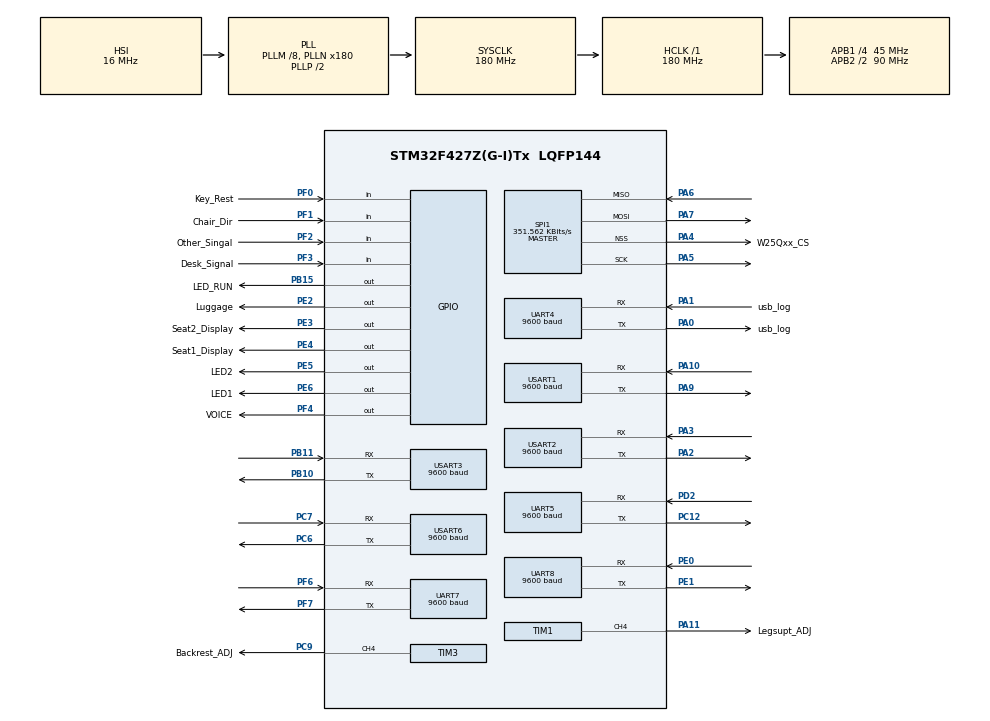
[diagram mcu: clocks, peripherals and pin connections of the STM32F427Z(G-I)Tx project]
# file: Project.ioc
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Dma.Request0=UART4_RX
Dma.Request1=USART1_RX
Dma.Request2=USART2_RX
Dma.Request3=USART3_RX
Dma.Request4=UART5_RX
Dma.Request5=USART6_RX
Dma.Request6=UART7_RX
Dma.Request7=UART8_RX
Dma.UART4_RX.0.Direction=DMA_PERIPH_TO_MEMORY
Dma.UART4_RX.0.FIFOMode=DMA_FIFOMODE_DISABLE
Dma.UART4_RX.0.Instance=DMA1_Stream2
Dma.UART4_RX.0.MemDataAlignment=DMA_MDATAALIGN_BYTE
Dma.UART4_RX.0.MemInc=DMA_MINC_ENABLE
Dma.UART4_RX.0.Mode=DMA_NORMAL
Dma.UART4_RX.0.PeriphDataAlignment=DMA_PDATAALIGN_BYTE
Dma.UART4_RX.0.PeriphInc=DMA_PINC_DISABLE
Dma.UART4_RX.0.Priority=DMA_PRIORITY_LOW
Dma.UART5_RX.4.Direction=DMA_PERIPH_TO_MEMORY
Dma.UART5_RX.4.FIFOMode=DMA_FIFOMODE_DISABLE
Dma.UART5_RX.4.Instance=DMA1_Stream0
Dma.UART5_RX.4.MemDataAlignment=DMA_MDATAALIGN_BYTE
Dma.UART5_RX.4.MemInc=DMA_MINC_ENABLE
Dma.UART5_RX.4.Mode=DMA_NORMAL
Dma.UART5_RX.4.PeriphDataAlignment=DMA_PDATAALIGN_BYTE
Dma.UART5_RX.4.PeriphInc=DMA_PINC_DISABLE
Dma.UART5_RX.4.Priority=DMA_PRIORITY_LOW
Dma.UART7_RX.6.Direction=DMA_PERIPH_TO_MEMORY
Dma.UART7_RX.6.FIFOMode=DMA_FIFOMODE_DISABLE
Dma.UART7_RX.6.Instance=DMA1_Stream3
Dma.UART7_RX.6.MemDataAlignment=DMA_MDATAALIGN_BYTE
Dma.UART7_RX.6.MemInc=DMA_MINC_ENABLE
Dma.UART7_RX.6.Mode=DMA_NORMAL
Dma.UART7_RX.6.PeriphDataAlignment=DMA_PDATAALIGN_BYTE
Dma.UART7_RX.6.PeriphInc=DMA_PINC_DISABLE
Dma.UART7_RX.6.Priority=DMA_PRIORITY_LOW
Dma.UART8_RX.7.Direction=DMA_PERIPH_TO_MEMORY
Dma.UART8_RX.7.FIFOMode=DMA_FIFOMODE_DISABLE
Dma.UART8_RX.7.Instance=DMA1_Stream6
Dma.UART8_RX.7.MemDataAlignment=DMA_MDATAALIGN_BYTE
Dma.UART8_RX.7.MemInc=DMA_MINC_ENABLE
Dma.UART8_RX.7.Mode=DMA_NORMAL
Dma.UART8_RX.7.PeriphDataAlignment=DMA_PDATAALIGN_BYTE
Dma.UART8_RX.7.PeriphInc=DMA_PINC_DISABLE
Dma.UART8_RX.7.Priority=DMA_PRIORITY_LOW
Dma.USART1_RX.1.Direction=DMA_PERIPH_TO_MEMORY
Dma.USART1_RX.1.FIFOMode=DMA_FIFOMODE_DISABLE
Dma.USART1_RX.1.Instance=DMA2_Stream2
Dma.USART1_RX.1.MemDataAlignment=DMA_MDATAALIGN_BYTE
Dma.USART1_RX.1.MemInc=DMA_MINC_ENABLE
Dma.USART1_RX.1.Mode=DMA_NORMAL
Dma.USART1_RX.1.PeriphDataAlignment=DMA_PDATAALIGN_BYTE
Dma.USART1_RX.1.PeriphInc=DMA_PINC_DISABLE
Dma.USART1_RX.1.Priority=DMA_PRIORITY_LOW
Dma.USART2_RX.2.Direction=DMA_PERIPH_TO_MEMORY
Dma.USART2_RX.2.FIFOMode=DMA_FIFOMODE_DISABLE
Dma.USART2_RX.2.Instance=DMA1_Stream5
Dma.USART2_RX.2.MemDataAlignment=DMA_MDATAALIGN_BYTE
Dma.USART2_RX.2.MemInc=DMA_MINC_ENABLE
Dma.USART2_RX.2.Mode=DMA_NORMAL
Dma.USART2_RX.2.PeriphDataAlignment=DMA_PDATAALIGN_BYTE
Dma.USART2_RX.2.PeriphInc=DMA_PINC_DISABLE
Dma.USART2_RX.2.Priority=DMA_PRIORITY_LOW
Dma.USART3_RX.3.Direction=DMA_PERIPH_TO_MEMORY
Dma.USART3_RX.3.FIFOMode=DMA_FIFOMODE_DISABLE
Dma.USART3_RX.3.Instance=DMA1_Stream1
Dma.USART3_RX.3.MemDataAlignment=DMA_MDATAALIGN_BYTE
Dma.USART3_RX.3.MemInc=DMA_MINC_ENABLE
Dma.USART3_RX.3.Mode=DMA_NORMAL
Dma.USART3_RX.3.PeriphDataAlignment=DMA_PDATAALIGN_BYTE
Dma.USART3_RX.3.PeriphInc=DMA_PINC_DISABLE
Dma.USART3_RX.3.Priority=DMA_PRIORITY_LOW
Dma.USART6_RX.5.Direction=DMA_PERIPH_TO_MEMORY
Dma.USART6_RX.5.FIFOMode=DMA_FIFOMODE_DISABLE
Dma.USART6_RX.5.Instance=DMA2_Stream1
Dma.USART6_RX.5.MemDataAlignment=DMA_MDATAALIGN_BYTE
Dma.USART6_RX.5.MemInc=DMA_MINC_ENABLE
Dma.USART6_RX.5.Mode=DMA_NORMAL
Dma.USART6_RX.5.PeriphDataAlignment=DMA_PDATAALIGN_BYTE
Dma.USART6_RX.5.PeriphInc=DMA_PINC_DISABLE
Dma.USART6_RX.5.Priority=DMA_PRIORITY_LOW
Mcu.Family=STM32F4
Mcu.Name=STM32F427Z(G-I)Tx
Mcu.Package=LQFP144
NVIC.DMA1_Stream0_IRQn=true\:0\:0\:false\:false\:true\:false\:true\:true
NVIC.DMA1_Stream1_IRQn=true\:0\:0\:false\:false\:true\:false\:true\:true
NVIC.DMA1_Stream2_IRQn=true\:0\:0\:false\:false\:true\:false\:true\:true
NVIC.DMA1_Stream3_IRQn=true\:0\:0\:false\:false\:true\:false\:true\:true
NVIC.DMA1_Stream5_IRQn=true\:0\:0\:false\:false\:true\:false\:true\:true
NVIC.DMA1_Stream6_IRQn=true\:0\:0\:false\:false\:true\:false\:true\:true
NVIC.DMA2_Stream1_IRQn=true\:0\:0\:false\:false\:true\:false\:true\:true
NVIC.DMA2_Stream2_IRQn=true\:0\:0\:false\:false\:true\:false\:true\:true
NVIC.PriorityGroup=NVIC_PRIORITYGROUP_4
NVIC.UART4_IRQn=true\:0\:0\:false\:false\:true\:true\:true\:true
NVIC.UART5_IRQn=true\:0\:0\:false\:false\:true\:true\:true\:true
NVIC.UART7_IRQn=true\:0\:0\:false\:false\:true\:true\:true\:true
NVIC.UART8_IRQn=true\:0\:0\:false\:false\:true\:true\:true\:true
NVIC.USART1_IRQn=true\:0\:0\:false\:false\:true\:true\:true\:true
NVIC.USART2_IRQn=true\:0\:0\:false\:false\:true\:true\:true\:true
NVIC.USART3_IRQn=true\:0\:0\:false\:false\:true\:true\:true\:true
NVIC.USART6_IRQn=true\:5\:0\:true\:false\:true\:true\:true\:true
PA0/WKUP.GPIO_Label=usb_log
PA0/WKUP.Mode=Asynchronous
PA0/WKUP.Signal=UART4_TX
PA1.GPIO_Label=usb_log
PA1.Mode=Asynchronous
PA1.Signal=UART4_RX
PA10.Mode=Asynchronous
PA10.Signal=USART1_RX
PA11.GPIO_Label=Legsupt_ADJ
PA11.GPIO_Speed=GPIO_SPEED_FREQ_MEDIUM
PA11.Signal=S_TIM1_CH4
PA13.Mode=Serial_Wire
PA13.Signal=SYS_JTMS-SWDIO
PA14.Mode=Serial_Wire
PA14.Signal=SYS_JTCK-SWCLK
PA2.Mode=Asynchronous
PA2.Signal=USART2_TX
PA3.Mode=Asynchronous
PA3.Signal=USART2_RX
PA4.GPIO_Label=W25Qxx_CS
PA4.Mode=NSS_Signal_Hard_Output
PA4.Signal=SPI1_NSS
PA5.Mode=Full_Duplex_Master
PA5.Signal=SPI1_SCK
PA6.Mode=Full_Duplex_Master
PA6.Signal=SPI1_MISO
PA7.Mode=Full_Duplex_Master
PA7.Signal=SPI1_MOSI
PA9.Mode=Asynchronous
PA9.Signal=USART1_TX
PB10.Mode=Asynchronous
PB10.Signal=USART3_TX
PB11.Mode=Asynchronous
PB11.Signal=USART3_RX
PB15.GPIO_Label=LED_RUN
PB15.Signal=GPIO_Output
PC12.Mode=Asynchronous
PC12.Signal=UART5_TX
PC6.Mode=Asynchronous
PC6.Signal=USART6_TX
PC7.Mode=Asynchronous
PC7.Signal=USART6_RX
PC9.GPIO_Label=Backrest_ADJ
PC9.GPIO_Speed=GPIO_SPEED_FREQ_MEDIUM
PC9.Signal=S_TIM3_CH4
PD2.Mode=Asynchronous
PD2.Signal=UART5_RX
PE0.Mode=Asynchronous
PE0.Signal=UART8_RX
PE1.Mode=Asynchronous
PE1.Signal=UART8_TX
PE2.GPIO_Label=Luggage
PE2.Signal=GPIO_Output
PE3.GPIO_Label=Seat2_Display
PE3.Signal=GPIO_Output
PE4.GPIO_Label=Seat1_Display
PE4.Signal=GPIO_Output
PE5.GPIO_Label=LED2
PE5.Signal=GPIO_Output
PE6.GPIO_Label=LED1
PE6.Signal=GPIO_Output
PF0.GPIO_Label=Key_Rest
PF0.Signal=GPIO_Input
PF1.GPIO_Label=Chair_Dir
PF1.GPIO_PuPd=GPIO_PULLUP
PF1.Signal=GPIO_Input
PF2.GPIO_Label=Other_Singal
PF2.GPIO_PuPd=GPIO_PULLUP
PF2.Signal=GPIO_Input
PF3.GPIO_Label=Desk_Signal
PF3.GPIO_PuPd=GPIO_PULLUP
PF3.Signal=GPIO_Input
PF4.GPIO_Label=VOICE
PF4.Signal=GPIO_Output
PF6.Mode=Asynchronous
PF6.Signal=UART7_RX
PF7.Mode=Asynchronous
PF7.Signal=UART7_TX
PH0/OSC_IN.Mode=HSE-External-Oscillator
PH0/OSC_IN.Signal=RCC_OSC_IN
PH1/OSC_OUT.Mode=HSE-External-Oscillator
PH1/OSC_OUT.Signal=RCC_OSC_OUT
ProjectManager.HeapSize=0x200
ProjectManager.StackSize=0x400
ProjectManager.TargetToolchain=MDK-ARM V5
RCC.48MHZClocksFreq_Value=90000000
RCC.AHBFreq_Value=180000000
RCC.APB1CLKDivider=RCC_HCLK_DIV4
RCC.APB1Freq_Value=45000000
RCC.APB1TimFreq_Value=90000000
RCC.APB2CLKDivider=RCC_HCLK_DIV2
RCC.APB2Freq_Value=90000000
RCC.APB2TimFreq_Value=180000000
RCC.CortexFreq_Value=180000000
RCC.HCLKFreq_Value=180000000
RCC.HSE_VALUE=25000000
RCC.HSI_VALUE=16000000
RCC.LSE_VALUE=32768
RCC.PLLM=8
RCC.PLLN=180
RCC.SYSCLKFreq_VALUE=180000000
RCC.SYSCLKSource=RCC_SYSCLKSOURCE_PLLCLK
RCC.VCOOutputFreq_Value=360000000
SH.S_TIM1_CH4.0=TIM1_CH4,PWM Generation4 CH4
SH.S_TIM3_CH4.0=TIM3_CH4,PWM Generation4 CH4
SPI1.BaudRatePrescaler=SPI_BAUDRATEPRESCALER_256
SPI1.CLKPhase=SPI_PHASE_2EDGE
SPI1.CLKPolarity=SPI_POLARITY_HIGH
SPI1.CRCCalculation=SPI_CRCCALCULATION_ENABLE
SPI1.CRCPolynomial=X0+X1+X2
SPI1.CalculateBaudRate=351.562 KBits/s
SPI1.Direction=SPI_DIRECTION_2LINES
SPI1.Mode=SPI_MODE_MASTER
SPI1.VirtualNSS=VM_NSSHARD
SPI1.VirtualType=VM_MASTER
TIM1.AutoReloadPreload=TIM_AUTORELOAD_PRELOAD_ENABLE
TIM1.Channel-PWM\ Generation4\ CH4=TIM_CHANNEL_4
TIM1.Period=1000-1
TIM1.Prescaler=90-1
TIM3.AutoReloadPreload=TIM_AUTORELOAD_PRELOAD_ENABLE
TIM3.Channel-PWM\ Generation4\ CH4=TIM_CHANNEL_4
TIM3.Period=1000-1
TIM3.Prescaler=90-1
TIM3.Pulse-PWM\ Generation4\ CH4=5000
UART4.BaudRate=9600
UART4.VirtualMode=Asynchronous
UART5.BaudRate=9600
UART5.VirtualMode=Asynchronous
UART7.BaudRate=9600
UART7.VirtualMode=Asynchronous
UART8.BaudRate=9600
UART8.VirtualMode=Asynchronous
USART1.BaudRate=9600
USART1.VirtualMode=VM_ASYNC
USART2.BaudRate=9600
USART2.VirtualMode=VM_ASYNC
USART3.BaudRate=9600
USART3.VirtualMode=VM_ASYNC
USART6.BaudRate=9600
USART6.VirtualMode=VM_ASYNC
board=custom

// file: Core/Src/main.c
/* USER CODE BEGIN Header */
/**
 ******************************************************************************
 * @file           : main.c
 * @brief          : Main program body
 ******************************************************************************
 * @attention
 *
 * Copyright (c) 2024 STMicroelectronics.
 * All rights reserved.
 *
 * This software is licensed under terms that can be found in the LICENSE file
 * in the root directory of this software component.
 * If no LICENSE file comes with this software, it is provided AS-IS.
 *
 ******************************************************************************
 */
/* USER CODE END Header */
#include "main.h"
#include "dma.h"
#include "spi.h"
#include "tim.h"
#include "usart.h"
#include "gpio.h"

/* USER CODE BEGIN PV */
uint8_t rec_buf[13];
uint16_t pindex =0;
/* USER CODE END PV */

void SystemClock_Config(void);
/* USER CODE BEGIN PFP */

/* dma it 回调函数 */
// void HAL_UART_TxCpltCallback(UART_HandleTypeDef *huart)
// {
//     if (huart == &huart4)
//         HAL_GPIO_TogglePin(LED_GPIO_Port, LED_Pin);
// }

// /* dma it 回调函数 */
// void HAL_UART_RxCpltCallback(UART_HandleTypeDef *huart)
// {
//     /* 复位DMA中断接收(mormal模式) */
//     if (HAL_UART_Receive_DMA(&huart4, rec_buf, sizeof(rec_buf)) != HAL_OK)
//     {
//         Error_Handler();
//     }
//     /* 判断串口 */
//     if (huart == &huart4)
//     {
//         HAL_UART_Transmit_DMA(&huart4, rec_buf, sizeof(rec_buf));
//         HAL_UART_Transmit_IT(&huart4, rec_buf, sizeof(rec_buf));
//         HAL_UART_Transmit(&huart4, rec_buf, sizeof(rec_buf),HAL_MAX_DELAY);
//     }
// }

/* idel中断接收回调 */
void HAL_UARTEx_RxEventCallback(UART_HandleTypeDef *huart, uint16_t Size)
{
    HAL_UART_Transmit_DMA(&huart4, rec_buf, Size);

    HAL_UARTEx_ReceiveToIdle_DMA(&huart4, rec_buf, sizeof(rec_buf));
    /* 关闭dma接收过半中断 */
    __HAL_DMA_DISABLE_IT(&hdma_uart4_rx, DMA_IT_HT);
}

/* USER CODE END PFP */

int main(void)
{

  /* MCU Configuration--------------------------------------------------------*/

  /* Reset of all peripherals, Initializes the Flash interface and the Systick. */
  HAL_Init();

  /* Configure the system clock */
  SystemClock_Config();

  /* Initialize all configured peripherals */
  MX_GPIO_Init();
  MX_DMA_Init();
  MX_UART4_Init();
  MX_TIM3_Init();
  MX_USART1_UART_Init();
  MX_USART2_UART_Init();
  MX_USART3_UART_Init();
  MX_UART5_Init();
  MX_USART6_UART_Init();
  MX_UART7_Init();
  MX_UART8_Init();
  MX_SPI1_Init();
  MX_TIM1_Init();
  /* USER CODE BEGIN 2 */
    // if (HAL_UART_Receive_DMA(&huart4, rec_buf, sizeof(rec_buf)) != HAL_OK)
    // {
    //     Error_Handler();
    // }

    HAL_UARTEx_ReceiveToIdle_DMA(&huart4, rec_buf, sizeof(rec_buf));
    __HAL_DMA_DISABLE_IT(&hdma_uart4_rx, DMA_IT_HT);

    HAL_GPIO_WritePin(LED_GPIO_Port, LED_Pin, GPIO_PIN_RESET);
    //HAL_TIM_PWM_Start(&htim9, TIM_CHANNEL_1);
		HAL_TIM_PWM_Start(&htim3, TIM_CHANNEL_4);
  /* USER CODE END 2 */

  /* Infinite loop */
  /* USER CODE BEGIN WHILE */
    while (1)
    {
			//TIM9->CCR1=990;
			TIM3->CCR4=499;// 499->2.5v 999->5v

			HAL_Delay(1);
        // Usart1Printf("hello%d\n", 123);
        // HAL_Delay(100);
        //  HAL_GPIO_TogglePin(LED_GPIO_Port, LED_Pin);
        //  HAL_Delay(10);
    /* USER CODE END WHILE */

    }
}

void SystemClock_Config(void)
{
  RCC_OscInitTypeDef RCC_OscInitStruct = {0};
  RCC_ClkInitTypeDef RCC_ClkInitStruct = {0};

  /** Configure the main internal regulator output voltage
  */
  __HAL_RCC_PWR_CLK_ENABLE();
  __HAL_PWR_VOLTAGESCALING_CONFIG(PWR_REGULATOR_VOLTAGE_SCALE1);

  /** Initializes the RCC Oscillators according to the specified parameters
  * in the RCC_OscInitTypeDef structure.
  */
  RCC_OscInitStruct.OscillatorType = RCC_OSCILLATORTYPE_HSI;
  RCC_OscInitStruct.HSIState = RCC_HSI_ON;
  RCC_OscInitStruct.HSICalibrationValue = RCC_HSICALIBRATION_DEFAULT;
  RCC_OscInitStruct.PLL.PLLState = RCC_PLL_ON;
  RCC_OscInitStruct.PLL.PLLSource = RCC_PLLSOURCE_HSI;
  RCC_OscInitStruct.PLL.PLLM = 8;
  RCC_OscInitStruct.PLL.PLLN = 180;
  RCC_OscInitStruct.PLL.PLLP = RCC_PLLP_DIV2;
  RCC_OscInitStruct.PLL.PLLQ = 4;
  if (HAL_RCC_OscConfig(&RCC_OscInitStruct) != HAL_OK)
  {
    Error_Handler();
  }

  /** Activate the Over-Drive mode
  */
  if (HAL_PWREx_EnableOverDrive() != HAL_OK)
  {
    Error_Handler();
  }

  /** Initializes the CPU, AHB and APB buses clocks
  */
  RCC_ClkInitStruct.ClockType = RCC_CLOCKTYPE_HCLK|RCC_CLOCKTYPE_SYSCLK
                              |RCC_CLOCKTYPE_PCLK1|RCC_CLOCKTYPE_PCLK2;
  RCC_ClkInitStruct.SYSCLKSource = RCC_SYSCLKSOURCE_PLLCLK;
  RCC_ClkInitStruct.AHBCLKDivider = RCC_SYSCLK_DIV1;
  RCC_ClkInitStruct.APB1CLKDivider = RCC_HCLK_DIV4;
  RCC_ClkInitStruct.APB2CLKDivider = RCC_HCLK_DIV2;

  if (HAL_RCC_ClockConfig(&RCC_ClkInitStruct, FLASH_LATENCY_5) != HAL_OK)
  {
    Error_Handler();
  }
}

void Error_Handler(void)
{
    __disable_irq();
    while (1)
    {
    }
}
